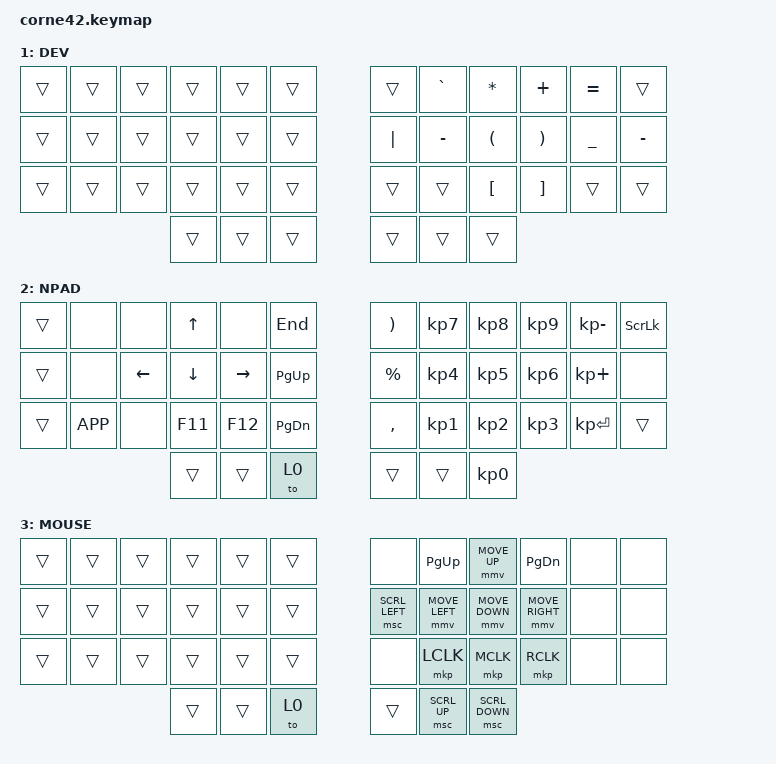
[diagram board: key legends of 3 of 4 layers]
/*
 * Copyright (c) 2020 The ZMK Contributors
 *
 * SPDX-License-Identifier: MIT
 */

#include <behaviors.dtsi>
#include <dt-bindings/zmk/keys.h>
#include <dt-bindings/zmk/bt.h>
#include <dt-bindings/zmk/ext_power.h>
#include <dt-bindings/zmk/outputs.h>
#include <dt-bindings/zmk/mouse.h>

#define HYPER LC(LS(LG(LALT)))
#define MEH LC(LALT(LCTRL))
#define SUPER LG(LALT(LCTRL))

#define QUICK_TAP_MS 175

// Key position definitions for home row mods (Corne 42)
#define KEYS_L 0 1 2 3 4 5 12 13 14 15 16 17 24 25 26 27 28 29  // Left-hand keys by number
#define KEYS_R 6 7 8 9 10 11 18 19 20 21 22 23 30 31 32 33 34 35  // Right-hand keys by number
#define THUMBS 36 37 38 39 40 41                                 // Thumb keys by number (LH0 LH1 LH2 RH0 RH1 RH2)

#define BASE 0
#define DEV 1
#define NPAD 2
#define MOUSE 3

/ {
    behaviors {
        hml: home_row_mod_left {
            compatible = "zmk,behavior-hold-tap";
            label = "LEFT_HAND_HRM";
            #binding-cells = <2>;
            flavor = "balanced";
            tapping-term-ms = <280>;
            quick-tap-ms = <175>;
            require-prior-idle-ms = <150>;
            hold-trigger-on-release;
            hold-trigger-key-positions = <KEYS_R THUMBS>;
            bindings = <&kp>, <&kp>;
        };

        hmr: home_row_mod_right {
            compatible = "zmk,behavior-hold-tap";
            label = "RIGHT_HAND_HRM";
            #binding-cells = <2>;
            flavor = "balanced";
            tapping-term-ms = <280>;
            quick-tap-ms = <175>;
            require-prior-idle-ms = <150>;
            hold-trigger-on-release;
            hold-trigger-key-positions = <KEYS_L THUMBS>;
            bindings = <&kp>, <&kp>;
        };

        ltl: layer_tap_left {
            compatible = "zmk,behavior-hold-tap";
            label = "LEFT_HAND_LAYER_TAP";
            #binding-cells = <2>;
            flavor = "balanced";
            tapping-term-ms = <280>;
            quick-tap-ms = <175>;
            require-prior-idle-ms = <150>;
            hold-trigger-on-release;
            hold-trigger-key-positions = <KEYS_R THUMBS>;
            bindings = <&mo>, <&kp>;
        };

        ltr: layer_tap_right {
            compatible = "zmk,behavior-hold-tap";
            label = "RIGHT_HAND_LAYER_TAP";
            #binding-cells = <2>;
            flavor = "balanced";
            tapping-term-ms = <280>;
            quick-tap-ms = <175>;
            require-prior-idle-ms = <150>;
            hold-trigger-on-release;
            hold-trigger-key-positions = <KEYS_L THUMBS>;
            bindings = <&mo>, <&kp>;
        };
    };
    keymap {
        compatible = "zmk,keymap";
        BASE {
            bindings = <
   &kp TAB    &kp Q      &ltl MOUSE W    &kp E           &kp R            &kp T                                &kp Y                  &kp U           &kp I           &kp O            &kp P           &kp BSLH
   &kp ESC    &kp A      &hml LGUI S     &hml LALT D     &hml LCTRL F     &ltl NPAD G                          &ltr NPAD H            &hmr RCTRL J    &hmr RALT K     &hmr RGUI L      &kp SEMI        &kp SQT
   &kp GRAVE  &kp Z      &kp X           &kp C           &kp V            &kp B                                &kp N                  &kp M           &kp COMMA       &kp DOT          &kp FSLH        &kp PG_UP
                                                         &kp BSPC         &kp LSHFT    &ltl DEV LALT  &kp RET  &hmr RSHFT &caps_word  &kp SPACE
            >;
        };
        DEV {
            bindings = <
   &trans     &trans     &trans          &trans          &trans           &trans                               &trans                 &kp GRAVE       &kp STAR        &kp PLUS         &kp EQUAL       &trans
   &trans     &trans     &trans          &trans          &trans           &trans                               &kp PIPE               &kp MINUS       &kp LPAR        &kp RPAR         &kp UNDERSCORE  &kp MINUS
   &trans     &trans     &trans          &trans          &trans           &trans                               &trans                 &trans          &kp LBKT        &kp RBKT         &trans          &trans
                                                         &trans           &trans       &trans         &trans   &trans                 &trans
            >;
        };
        NPAD {
            bindings = <
   &trans     &none      &none           &kp UP_ARROW    &none            &kp END                              &kp RPAR               &kp KP_N7       &kp KP_N8       &kp KP_N9        &kp KP_MINUS    &kp SCROLLLOCK
   &trans     &none      &kp LEFT_ARROW  &kp DOWN_ARROW  &kp RIGHT_ARROW  &kp PG_UP                            &kp PERCENT            &kp KP_N4       &kp KP_N5       &kp KP_N6        &kp KP_PLUS     &none
   &trans     &kp K_APP  &none           &kp F11         &kp F12          &kp PG_DN                            &kp COMMA              &kp KP_N1       &kp KP_N2       &kp KP_N3        &kp KP_ENTER    &trans
                                                         &trans           &trans       &to 0          &trans   &trans                 &kp KP_N0
            >;
        };
        MOUSE {
            bindings = <
   &trans     &trans     &trans          &trans          &trans           &trans                               &none                  &kp PG_UP       &mmv MOVE_UP    &kp PG_DN        &none           &none
   &trans     &trans     &trans          &trans          &trans           &trans                               &msc SCRL_LEFT         &mmv MOVE_LEFT  &mmv MOVE_DOWN  &mmv MOVE_RIGHT  &none           &none
   &trans     &trans     &trans          &trans          &trans           &trans                               &none                  &mkp LCLK       &mkp MCLK       &mkp RCLK        &none           &none
                                                         &trans           &trans       &to 0          &trans   &msc SCRL_UP           &msc SCRL_DOWN
            >;
        };
    };
};
